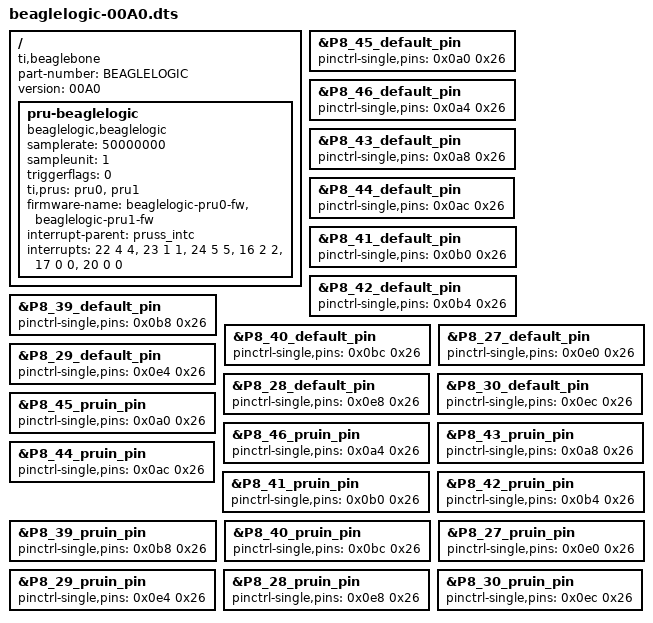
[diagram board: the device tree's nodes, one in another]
/dts-v1/;
/plugin/;

/ {
        compatible = "ti,beaglebone", "ti,beaglebone-black", "ti,beaglebone-green";
        part-number = "BEAGLELOGIC";
        version = "00A0";

        fragment@0  { target = <&P8_45_default_pin>; __overlay__ { pinctrl-single,pins = <0x0a0 0x26>; }; };
        fragment@1  { target = <&P8_46_default_pin>; __overlay__ { pinctrl-single,pins = <0x0a4 0x26>; }; };
        fragment@2  { target = <&P8_43_default_pin>; __overlay__ { pinctrl-single,pins = <0x0a8 0x26>; }; };
        fragment@3  { target = <&P8_44_default_pin>; __overlay__ { pinctrl-single,pins = <0x0ac 0x26>; }; };
        fragment@4  { target = <&P8_41_default_pin>; __overlay__ { pinctrl-single,pins = <0x0b0 0x26>; }; };
        fragment@5  { target = <&P8_42_default_pin>; __overlay__ { pinctrl-single,pins = <0x0b4 0x26>; }; };
        fragment@6  { target = <&P8_39_default_pin>; __overlay__ { pinctrl-single,pins = <0x0b8 0x26>; }; };
        fragment@7  { target = <&P8_40_default_pin>; __overlay__ { pinctrl-single,pins = <0x0bc 0x26>; }; };
        fragment@8  { target = <&P8_27_default_pin>; __overlay__ { pinctrl-single,pins = <0x0e0 0x26>; }; };
        fragment@9  { target = <&P8_29_default_pin>; __overlay__ { pinctrl-single,pins = <0x0e4 0x26>; }; };
        fragment@10 { target = <&P8_28_default_pin>; __overlay__ { pinctrl-single,pins = <0x0e8 0x26>; }; };
        fragment@11 { target = <&P8_30_default_pin>; __overlay__ { pinctrl-single,pins = <0x0ec 0x26>; }; };

        fragment@12 { target = <&P8_45_pruin_pin>; __overlay__ { pinctrl-single,pins = <0x0a0 0x26>; }; };
        fragment@13 { target = <&P8_46_pruin_pin>; __overlay__ { pinctrl-single,pins = <0x0a4 0x26>; }; };
        fragment@14 { target = <&P8_43_pruin_pin>; __overlay__ { pinctrl-single,pins = <0x0a8 0x26>; }; };
        fragment@15 { target = <&P8_44_pruin_pin>; __overlay__ { pinctrl-single,pins = <0x0ac 0x26>; }; };
        fragment@16 { target = <&P8_41_pruin_pin>; __overlay__ { pinctrl-single,pins = <0x0b0 0x26>; }; };
        fragment@17 { target = <&P8_42_pruin_pin>; __overlay__ { pinctrl-single,pins = <0x0b4 0x26>; }; };
        fragment@18 { target = <&P8_39_pruin_pin>; __overlay__ { pinctrl-single,pins = <0x0b8 0x26>; }; };
        fragment@19 { target = <&P8_40_pruin_pin>; __overlay__ { pinctrl-single,pins = <0x0bc 0x26>; }; };
        fragment@20 { target = <&P8_27_pruin_pin>; __overlay__ { pinctrl-single,pins = <0x0e0 0x26>; }; };
        fragment@21 { target = <&P8_29_pruin_pin>; __overlay__ { pinctrl-single,pins = <0x0e4 0x26>; }; };
        fragment@22 { target = <&P8_28_pruin_pin>; __overlay__ { pinctrl-single,pins = <0x0e8 0x26>; }; };
        fragment@23 { target = <&P8_30_pruin_pin>; __overlay__ { pinctrl-single,pins = <0x0ec 0x26>; }; };

        fragment@24 {
                target-path = "/";
                __overlay__ {
                        pru-beaglelogic {
                                compatible = "beaglelogic,beaglelogic";
                                samplerate = <50000000>;
                                sampleunit = <1>;
                                triggerflags = <0>;

                                ti,prus = <&pru0>, <&pru1>;
                                firmware-name = "beaglelogic-pru0-fw", "beaglelogic-pru1-fw";
                                interrupt-parent = <&pruss_intc>;
                                interrupts = <22 4 4>, <23 1 1>, <24 5 5>,
                                             <16 2 2>, <17 0 0>, <20 0 0>;
                                interrupt-names = "from_bl_1", "to_bl", "from_bl_2",
                                                  "pru0_to_arm", "arm_to_pru0", "pru1_to_pru0";
                        };
                };
        };
};
